# RS1xxxx register map
Vendor: Silicon Lab Inc.; Series: ARMCM4; File version: 1.2
CPU: CM4 r1p0, little endian, MPU, FPU, 6 interrupt priority bits
Registers are 32-bit, read-write, reset 0x0 unless marked. A register's access mark holds for its fields unless they carry their own. Offsets are from the block's base; [hi:lo] are bit positions; lines under a group give offsets from that group; {n}, {i} and the like mark numbered series.

## MCU_RET — NPSS has Retention domain logic which is a power domain . This domain consisted all logic which will turned off if none of the M4 memories are retained.
Base 0x24048600
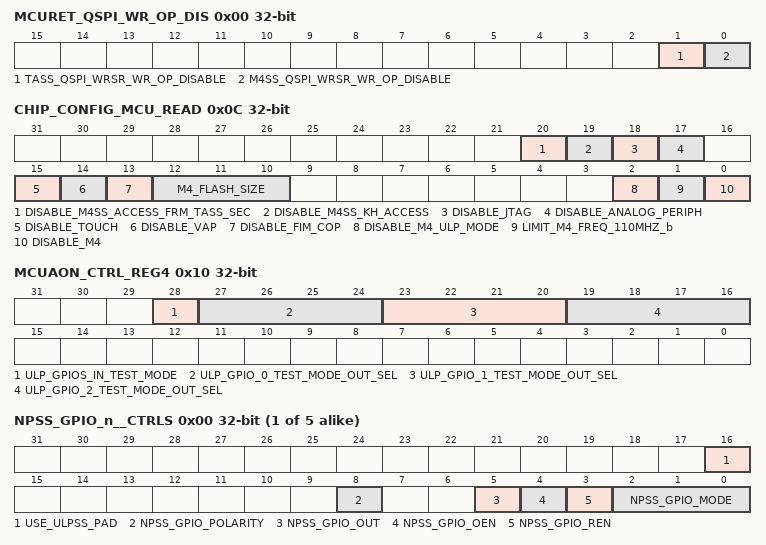
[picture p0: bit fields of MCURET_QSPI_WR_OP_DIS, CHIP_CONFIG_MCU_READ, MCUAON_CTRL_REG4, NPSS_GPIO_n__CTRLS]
0x00 MCURET_QSPI_WR_OP_DIS
  [1] TASS_QSPI_WRSR_WR_OP_DISABLE ro — TASS Write operation disable to Flash. 1 - Write Operation to Flash is not allowed. 0 - Write Operation to Flash is allowed.
  [0] M4SS_QSPI_WRSR_WR_OP_DISABLE — M4SS Write operation disable to Flash. 1 - Write Operation to Flash is not allowed. 0 - Write Operation to Flash is allowed.
0x04 MCURET_BOOTSTATUS ro
  [0] BOOT_STATUS — Boot Status/Configuration information to MCU
0x0C CHIP_CONFIG_MCU_READ ro — MCURET BOOT Status
  [20] DISABLE_M4SS_ACCESS_FRM_TASS_SEC — When set, M4 can not access TASS memory or registers except for host communication registers
  [19] DISABLE_M4SS_KH_ACCESS — When set, disables access to key in the key holder from M4SS QSPI
  [18] DISABLE_JTAG — When set, disable JTAG interface(both M4 and TA)
  [17] DISABLE_ANALOG_PERIPH — When set, disables analog peripherals
  [15] DISABLE_TOUCH — When set, disables touch interface
  [14] DISABLE_VAP — When set, disables VAD
  [13] DISABLE_FIM_COP — When set, disable FIMV
  [12:10] M4_FLASH_SIZE — 0xx - Unrestricted 100 - Auto mode accesses to flash are restricted to 4 MBit 101 - Auto mode accesses to flash are restricted to 8 MBit 110 - Auto mode accesses to flash are restricted to 16 MBit 111 - Auto mode accesses to flash are restricted to 32 MBit
  [2] DISABLE_M4_ULP_MODE — When set, limits the M4SS SoC clock to Max clock/2
  [1] LIMIT_M4_FREQ_110MHZ_b — When set, limits the M4SS SoC clock to Max clock/2
  [0] DISABLE_M4 — When set, disables the M4 by clock gating and putting M4 in reset
0x10 MCUAON_CTRL_REG4 — MCURET Control Register4
  [28] ULP_GPIOS_IN_TEST_MODE — NPSS Test modes
  [27:24] ULP_GPIO_0_TEST_MODE_OUT_SEL — NPSS Test modes
  [23:20] ULP_GPIO_1_TEST_MODE_OUT_SEL — NPSS Test modes
  [19:16] ULP_GPIO_2_TEST_MODE_OUT_SEL — NPSS Test modes
{0x1C+4i} NPSS_GPIO_CNTRLn[{i}] (i=0..4) group — NPSS GPIO related registers (0-4)
  0x00 NPSS_GPIO_n__CTRLS — NPSS GPIO Control register
    [16] USE_ULPSS_PAD — Input from ULPSS GPIOs.
    [8] NPSS_GPIO_POLARITY — NPSS GPIO 0 Polarity 1 - When signal is High 0 - When signal is Ligh.
    [5] NPSS_GPIO_OUT — NPSS GPIO 0 Output value.
    [4] NPSS_GPIO_OEN — NPSS GPIO 0 Output Buffer Enable. 1- Input Direction 0- Output Direction.
    [3] NPSS_GPIO_REN — NPSS GPIO 0 Input Buffer Enable. 1- Enable 0- Disable.
    [2:0] NPSS_GPIO_MODE — NPSS GPIO 0 mode select.

## MCU_TEMP — The temperature sensor is used to read the temperature by using APB registers, which is access through direct to ULPSS system.
Base 0x24048500
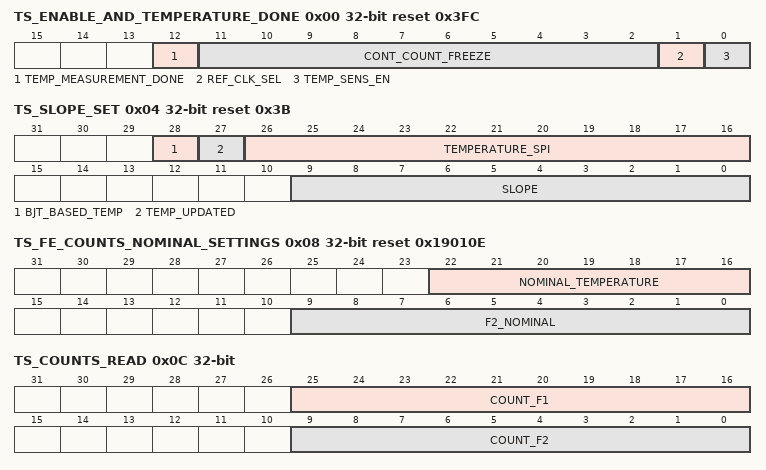
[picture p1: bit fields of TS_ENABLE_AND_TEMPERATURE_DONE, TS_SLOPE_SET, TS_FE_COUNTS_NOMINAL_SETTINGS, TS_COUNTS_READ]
0x00 TS_ENABLE_AND_TEMPERATURE_DONE reset 0x3FC — Temperature sensor enable and measurement calculation done indication register
  [12] TEMP_MEASUREMENT_DONE ro — temperature measurement done indication.
  [11:2] CONT_COUNT_FREEZE — Count of reference clock on which ptat clock counts
  [1] REF_CLK_SEL — if this bit is zero then reference RO clock from analog,else this bit is one then MCU FSM clock
  [0] TEMP_SENS_EN wo — Temperature sensing enable,self clearing register
0x04 TS_SLOPE_SET reset 0x3B — temperature sensor slope set(slope will be change with respect to temperature change)
  [28] BJT_BASED_TEMP — Temperature is updated through which is calculated using bjt based if bit is high(1) through spi and bit is low(0) then through calculation RO based
  [27] TEMP_UPDATED wo — temperature updated signal for the reg to capture this temperature.
  [26:16] TEMPERATURE_SPI — temperature known
  [9:0] SLOPE — This is one time measurement for one package after chip arrives from fab,this is signed bit.
0x08 TS_FE_COUNTS_NOMINAL_SETTINGS reset 0x19010E — determine calibrated temperature
  [22:16] NOMINAL_TEMPERATURE — calibrated temperature
  [9:0] F2_NOMINAL — ptat clock count during calibration,This will vary with chip to chip.
0x0C TS_COUNTS_READ ro — temperature sensor count read.
  [25:16] COUNT_F1, [9:0] COUNT_F2
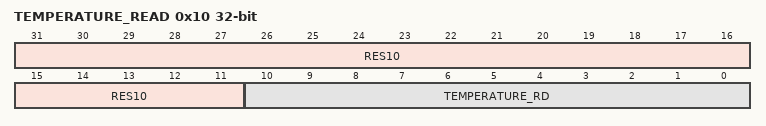
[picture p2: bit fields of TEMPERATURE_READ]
0x10 TEMPERATURE_READ — read the temperature
  [31:11] RES10 — reserved10
  [10:0] TEMPERATURE_RD ro — Temperature value for read in signed format
